# lilium_network register map
Vendor: Nordic Semiconductor; Series: nrfXX; File version: 1
CPU: CM33 r0p4, little endian, MPU, no FPU, 3 interrupt priority bits, 30 interrupts
Registers are 32-bit, read-write, reset 0x0 unless marked. A register's access mark holds for its fields unless they carry their own. Offsets are from the block's base; [hi:lo] are bit positions; lines under a group give offsets from that group; {n}, {i} and the like mark numbered series; 'fields as' and 'values as' point back to an identical list.

## RADIO (part 2 of 3) — 2.4 GHz radio
Base 0x41008000
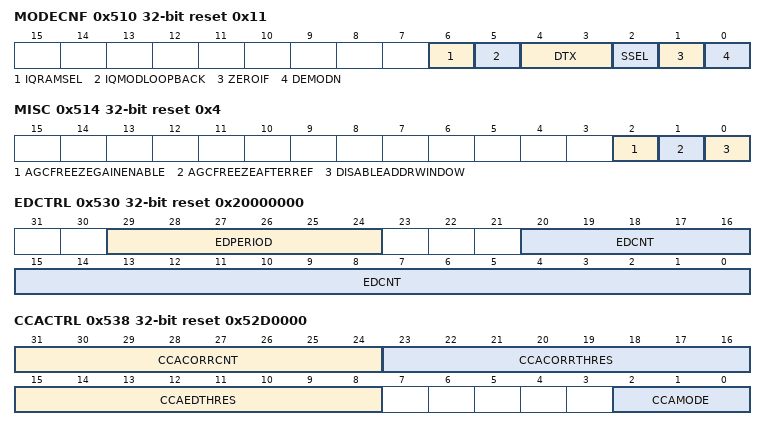
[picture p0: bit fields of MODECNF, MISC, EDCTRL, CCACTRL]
0x510 MODECNF reset 0x11 — Radio mode configuration register
  [6] IQRAMSEL — IQ RAM select
    0=off (IQ RAM select off); 1=on (IQ RAM select on)
  [5] IQMODLOOPBACK — Loopback from IQ modulator TODO: is it a good place?
    0=Off (Digital loopback off); 1=On (Digital loopback on)
  [4:3] DTX — Default TX value. Specifies what the RADIO will transmit when it is not started, i.e. between: RADIO.EVENTS_READY and RADIO.TASKS_START RADIO.EVENTS_END and RADIO.TASKS_START RADIO.EVENTS_END and RADIO.EVENTS_DISABLED)
    0=B1 (Transmit '1'); 1=B0 (Transmit '0'); 2=Center (Transmit center frequency When tuning the crystal for centre frequency, the RADIO must be set in DTX = Center mode to be able to achieve the expected accuracy. This is only a valid setting for Nrf_1Mbit, Nrf_2Mbit, Nrf_250kbit, Ble_1Mbit and Ble_2Mbit.)
  [2] SSEL — Sideband select
    0=Low (Low-side LO); 1=High-side LO
  [1] ZEROIF — Zero-IF mode
    0=Default mode (heterodyne); 1=Zero-IF mode
  [0] DEMODN — Demodulator mode override value
    0=Standard demodulator mode; 1=Hyper demodulator mode
0x514 MISC reset 0x4 — Misc configuration collection (to be renamed when more bits are defined)
  [2] AGCFREEZEGAINENABLE — Override AGC gain setting during CTE (from QOVERRIDE10)
    0=Adjust (AGC gain settings will keep adjusting during CTE); 1=Freeze (AGC gain settings will freeze (not keep adjusting) during CTE)
  [1] AGCFREEZEAFTERREF
    0=EntireCTE (Gain freeze will apply to whole CTE,); 1=AfterRefPeriod (Gain freeze will apply to only after reference period of CTE.)
  [0] DISABLEADDRWINDOW
    1=Disabled; 0=Enabled
0x520 STATE ro — Current radio state
  [3:0] STATE
    0=Disabled (RADIO is in the Disabled state); 1=RxRu (RADIO is in the RXRU state); 2=RxIdle (RADIO is in the RXIDLE state); 3=Rx (RADIO is in the RX state); 4=RxDisable (RADIO is in the RXDISABLED state); 9=TxRu (RADIO is in the TXRU state); 10=TxIdle (RADIO is in the TXIDLE state); 11=Tx (RADIO is in the TX state); 12=TxDisable (RADIO is in the TXDISABLED state)
0x530 EDCTRL reset 0x20000000 — IEEE 802.15.4 energy detect control TODO: review and maybe rename in IPS
  [29:24] EDPERIOD — IEEE 802.15.4 energy detect/cca period, 4us resolution
  [20:0] EDCNT — IEEE 802.15.4 energy detect loop count
0x534 EDSAMPLE ro — IEEE 802.15.4 energy detect level
  [7:0] EDLVL
0x538 CCACTRL reset 0x52D0000 — IEEE 802.15.4 clear channel assessment control
  [31:24] CCACORRCNT — Limit for occurances above CCACORRTHRES. When not equal to zero the corrolator based signal detect is enabled.
  [23:16] CCACORRTHRES — CCA correlator busy threshold. Only relevant to CarrierMode, CarrierAndEdMode, and CarrierOrEdMode.
  [15:8] CCAEDTHRES — CCA energy busy threshold. Used in all the CCA modes except CarrierMode.
  [2:0] CCAMODE — CCA mode of operation
    0=EdMode (Energy above threshold); 1=CarrierMode (Carrier seen); 2=CarrierAndEdMode (Energy above threshold AND carrier seen); 3=CarrierOrEdMode (Energy above threshold OR carrier seen); 4=EdModeTest1 (Energy above threshold test mode that will abort when first ED measurement over threshold is seen. No averaging.)
0x540 DATAWHITEIV reset 0x40 — Data whitening initial value TODO:move to FelisMAC
  [5:0] DATAWHITEIV
0x548 ACQINJ group — Unspecified
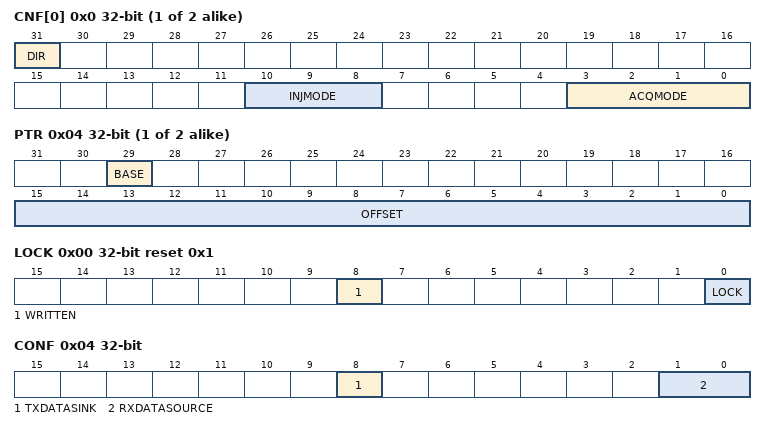
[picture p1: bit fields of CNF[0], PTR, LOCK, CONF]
  {0x0+4j} CNF[{j}] (j=0..1) — Description collection: Data acquisition capture mode
    [31] DIR — Data acquisition or injection
      0=Acq (Peripheral to memory); 1=Inj (Memory to peripheral)
    [10:8] INJMODE — Data hijack mode (Do not select the same SRC for one than more DMAs. otherwise higher index takes over control.)
      0=FeSrc (Pick up IQ samples from RAM as FrontEnd input (hijack ADC output)); 1=BbSrc (Pick up IQ samples from RAM as Radio BaseBand input); 2=TxSrc (Pick up Tx bits from RAM (skipping packet assembler as modulator input); 6=AdPllModSrc (Pick up arbitrary wave from RAM to ADPLL)
    [3:0] ACQMODE — Data acquisition capture mode
      0=AdcIQ (Logging ADCI and ADCQ); 2=AdcIQAndAgcGain (Logging ADCI, ADCQ and AGC gain settings); 3=AgcGainAndPkd (Logging AGC gain settings and peak detector outputs); 4=FeIQ (Logging FrontEnd sampleI and sampleQ); 5=BbIQ (Logging BaseBand I and Q); 6=BbStdOut (Logging BaseBand std demodulator outputs (original ones, not the delayed version)); 7=BbHypOut (Logging BaseBand hyp demodulator outputs); 8=BbStdHypMuxOut (Logging muxed demodulator outputs and flags); 12=AdPllTrace (ADPLL tracing)
{0x550+0x10*i} ACQINJDMA[{i}] (i=0..1) group — Unspecified
  0x00 ENABLE — Description cluster: Enable or disable data acquisition
    [0] ENABLE — Enable or disable data acquisition
      0=Disabled (Data acquisition is disabled); 1=Enabled (Data acquisition is enabled)
  0x04 PTR — Description cluster: ACQ DMA pointer
    [29] BASE, [15:0] OFFSET
  0x08 MAXCNT — Description cluster: Maximum number of 32-bit words to transfer
    [13:0] MAXCNT — Maximum number of 32-bit words to transfer
  0x0C AMOUNT ro — Description cluster: Number of 32-bit words transferred in the last transaction
    [13:0] AMOUNT — Number of 32-bit words transferred in the last transaction
0x570 TESTINTERFACE group — 2.4 GHz radio direct test interface
  0x00 TESTINTERFACE group — Unspecified
    0x00 LOCK ro reset 0x1 — Security LOCK for test interface
      [8] WRITTEN — Status bit indicating if write once register has been written to since last reset
        1=Written (Write once register has been written to and cannot be overwritten unless reset.); 0=Unwritten (Write once register has not been written to and can be overwritten.)
      [0] LOCK — Write once to permanently lock or unlock.
        1=Lock (Interface is locked and cannot be enabled.); 0=Unlock (Interface is unlocked and can be enabled.)
    0x04 CONF — CONFIG for PSEL test interface
      [8] TXDATASINK — Sink select for Tx Data input. TX clock source is always SphynxSupport
        0=FelisTx (TX data sink is FelisTx); 1=SphynxSupport (TX data sink is SphynxSupport)
      [1:0] RXDATASOURCE — Source select for Rx data GPIO output and Rx clock output. Can optionally output Tx data that is transmitted TX clock
        0=Standard (Data and clock source is from standard demodulator); 1=Hyper (Data and clock source is from hyper demodulator); 2=FelisTx (Data source is Tx data to SphynxSupport.); 3=MacTx (Data source is Tx data to FelisTx.)
  0x08 DEBUGPSEL group — Unspecified
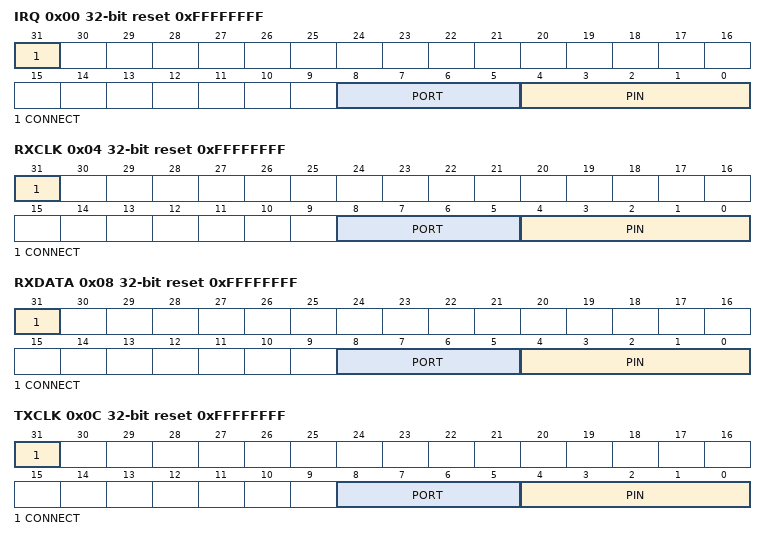
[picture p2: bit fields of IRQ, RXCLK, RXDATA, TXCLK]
    0x00 IRQ reset 0xFFFFFFFF — Pin select for RADIO irq
      [31] CONNECT — Connection
        1=Disconnected; 0=Connected
      [8:5] PORT — Port number
      [4:0] PIN — Pin number
    0x04 RXCLK reset 0xFFFFFFFF — Pin select for RXCLK
      fields as TESTINTERFACE.DEBUGPSEL.IRQ
    0x08 RXDATA reset 0xFFFFFFFF — Pin select for RXDATA
      fields as TESTINTERFACE.DEBUGPSEL.IRQ
    0x0C TXCLK reset 0xFFFFFFFF — Pin select for RADIO clock (direct mode, base band debug. txCk and ckDataIn signals)
      fields as TESTINTERFACE.DEBUGPSEL.IRQ
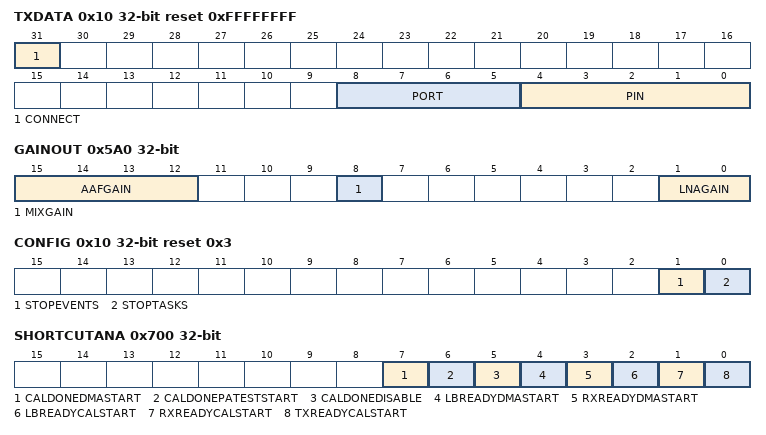
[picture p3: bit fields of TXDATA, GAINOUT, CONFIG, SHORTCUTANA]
    0x10 TXDATA reset 0xFFFFFFFF — Pin select for RADIO data (direct mode, base band debug. txRadioData and dataIn signals)
      fields as TESTINTERFACE.DEBUGPSEL.IRQ
0x5A0 GAINOUT ro — Gain readout (LNA_OUT_SPI for nrf52/53)
  [15:12] AAFGAIN, [8] MIXGAIN, [1:0] LNAGAIN
0x5B0 INTERCEPT group — Write 1 to a bit to arm the task/event at that index for a single intercept. Write 0 to a bit to disarm. After arming, the bit will be read out as 1 until the task/event has been intercepted or disarmed, after which it will be read out as 0. Both PPI-triggered and APB-triggered tasks will be intercepted. Only core-triggered events will be intercepted, not APB-triggered events.
  {0x0+4j} TASKS[{j}] (j=0..1) — Description collection:
    [31:0] ONEBITPERTASK
  {0x8+4j} EVENTS[{j}] (j=0..1) — Description collection:
    [31:0] ONEBITPEREVENT
  0x10 CONFIG reset 0x3 — Unspecified
    [1] STOPEVENTS, [0] STOPTASKS
0x700 SHORTCUTANA — Internal shortcuts for RADIO PHY
  [7] CALDONEDMASTART — Internal shortcut
  [6] CALDONEPATESTSTART — Internal shortcut
  [5] CALDONEDISABLE — Internal shortcut
  [4] LBREADYDMASTART — Internal shortcut
  [3] RXREADYDMASTART — Internal shortcut
  [2] LBREADYCALSTART — Internal shortcut
  [1] RXREADYCALSTART — Internal shortcut
  [0] TXREADYCALSTART — Internal shortcut
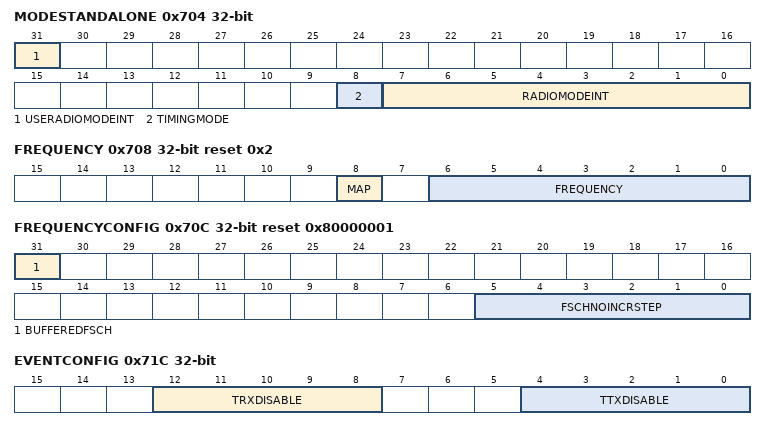
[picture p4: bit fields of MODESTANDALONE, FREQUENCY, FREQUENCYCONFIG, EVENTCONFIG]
0x704 MODESTANDALONE — Data rate and modulation when SPHYNX in standalone mode
  [31] USERADIOMODEINT — 0: use radioMode/radioModeUpdate from port (controlled from top), 1: use radioMode/radioModeUpdate from registers in this IP
  [8] TIMINGMODE — 0: Default ramp-up time, compatible with 180nm radio. 1: Fast ramp-up.
  [7:0] RADIOMODEINT — Internal radio mode consists of sSel, zeroIf, deModN and mode[3:0]
0x708 FREQUENCY reset 0x2
  [8] MAP — Channel map selection. 0: Channel map between 2400 MHZ to 2500 MHz, Frequency = 2400 + FREQUENCY (MHz). 1: Channel map between 2360 MHZ to 2460 MHz, Frequency = 2360 + FREQUENCY (MHz).
  [6:0] FREQUENCY — Radio channel frequency. Frequency = 2400 + FREQUENCY (MHz).
0x70C FREQUENCYCONFIG reset 0x80000001 — Configuration of frequency control
  [31] BUFFEREDFSCH — Set to high to buffer FREQUENCY register so that sub-modules in the MMI will only update next frequency config at TX_EN, RX_EN and LB_EN. Set to low if special test is needed for FS test.
  [5:0] FSCHNOINCRSTEP — Radio channel incremental step unit
0x710 TXPOWER — Output power
  [7:0] TXPOWER — RADIO output power
    {v}=Pos{v}dBm (+{v} dBm) (v=1..10); 0=0dBm; 255=Neg1dBm (-1 dBm); 254=Neg2dBm (-2 dBm); 252=Neg4dBm (-4 dBm); 248=Neg8dBm (-8 dBm); 244=Neg12dBm (-12 dBm); 240=Neg16dBm (-16 dBm); 236=Neg20dBm (-20 dBm); 226=Neg30dBm (-30 dBm); 216=Neg40dBm (-40 dBm); 186=Neg70dBm (-70 dBm)
0x714 TIFS — Interframe spacing in us
  [9:0] TIFS — Interframe spacing in us. Interframe space is the time interval between two consecutive packets. It is defined as the time, in microseconds, from the end of the last bit of the previous packet to the start of the first bit of the subsequent packet.
0x718 RSSISAMPLE ro reset 0x7F
  [6:0] RSSISAMPLE — RSSI sample result. The value of this register is read as a positive value while the actual received signal strength is a negative value. Actual received signal strength is therefore as follows: received signal strength = -A dBm.
0x71C EVENTCONFIG — Event configuration
  [12:8] TRXDISABLE — Transition time from RXDISABLE state to DISABLED state Configurable time, in us, between RADIO.EVENTS_END and RADIO.EVENTS_DISABLED when using the shortcut between RADIO.EVENTS_END and RADIO.TASKS_DISABLE. The minimum time between RADIO.TASKS_DISABLE and RADIO.EVENTS_DISABLED is described in electrical parameters. The minimum time will be used if the configured time is set shorter than the minimum time. Depending on configuration setting the DISABLED event may experience some jitter, see electrical parameters for more information. (unit: 1us)
  [4:0] TTXDISABLE — Transition time from TXDISABLE state to DISABLED state Configurable time, in us, between RADIO.EVENTS_END and RADIO.EVENTS_DISABLED when using the shortcut between RADIO.EVENTS_END and RADIO.TASKS_DISABLE. The minimum time between RADIO.TASKS_DISABLE and RADIO.EVENTS_DISABLED is described in the electrical parameters. The minimum time will be used if the configured time is set shorter than the minimum time. Depending on configuration setting the DISABLED event may experience some jitter, see electrical parameters for more information. Note: The RADIO shall be disabled as normal when DISABLE task is triggered, it is only the DISABLED event that can be delayed. Note: The TIFS mechanism shall not be affected by the value specified in this field. (unit: 1us)
0x720 CALIBRATION group — Unspecified
  0x00 TARGET — Select target for calibration
    [2:0] CALTARGET — Calibration target selection for calibration engine, 0: DC_CAL, 1: RC_CAL
  0x04 CONFIG — Configuration of manual calibration
    [31] CALMANUAL — 0: use hard-coded calibration timing, 1: use manual calibration timing above
    [29] CALINVERTCMP2 — 1: invert calCmp2 before it goes into calibration engine #2
    [28] CALINVERTCMP1 — 1: invert calCmp1 before it goes into calibration engine #1
    [26:24] CALBITS — Number of valid bits to be calibrated
    [23:16] CALTCOMPARE — Compare wait time
    [15:8] CALTSETTLE — Settle wait time
    [7:0] CALTSTART — Startup wait time
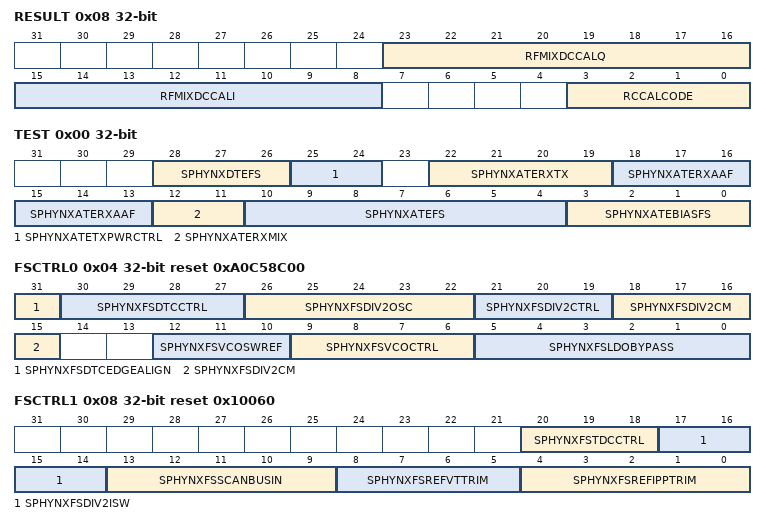
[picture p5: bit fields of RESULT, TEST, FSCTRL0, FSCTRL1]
  0x08 RESULT ro — Calibration result
    [23:16] RFMIXDCCALQ — Calibration result from DC offset calibration on channel Q
    [15:8] RFMIXDCCALI — Calibration result from DC offset calibration on channel I
    [3:0] RCCALCODE — Calibration result from RC calibration
0x730 SPHYNXANA group — Unspecified
  0x00 TEST — Control of analog and digital test bus output from Sphynx
    [28:26] SPHYNXDTEFS — Digital test enable for digital logic in analog macro
    [25:24] SPHYNXATETXPWRCTRL — Analog test enable for TX PWRCTRL
    [22:19] SPHYNXATERXTX — Analog test enable for RX TX
    [18:13] SPHYNXATERXAAF — Analog test enable for RX AAF
    [12:11] SPHYNXATERXMIX — Analog test enable for RX MIX
    [10:4] SPHYNXATEFS — Analog test enable for FS
    [3:0] SPHYNXATEBIASFS — Analog test enable for BIAS_FS
  0x04 FSCTRL0 reset 0xA0C58C00 — Control to frequency synthesizer of Sphynx
    [31] SPHYNXFSDTCEDGEALIGN — Resync at flip flop inside DTC
    [30:27] SPHYNXFSDTCCTRL — 0: controls bleed current from supply, 1: bypasses DTC to send XO out directly
    [26:22] SPHYNXFSDIV2OSC — Change back bias of NMOS in ROSC inside DIV2
    [21:19] SPHYNXFSDIV2CTRL — Spare, not used
    [18:15] SPHYNXFSDIV2CM — Set common mode for DIV2
    [12:10] SPHYNXFSVCOSWREF — FS swing calibration
    [9:6] SPHYNXFSVCOCTRL — Spare, not used
    [5:0] SPHYNXFSLDOBYPASS — Bypass FS LDOs
  0x08 FSCTRL1 reset 0x10060 — Control to frequency synthesizer of Sphynx
    [20:18] SPHYNXFSTDCCTRL — Spare, not used
    [17:14] SPHYNXFSDIV2ISW — Adjust voltage for back bias of injection switch
    [13:9] SPHYNXFSSCANBUSIN — DFT control/scan-in to AdPll. [4]: arstScan, [3]: scanTest, [2]: scanCk, [1]: scanEn, [0]: scanIn.
    [8:5] SPHYNXFSREFVTTRIM — For voltage tuning of reference
    [4:0] SPHYNXFSREFIPPTRIM — For current calibration
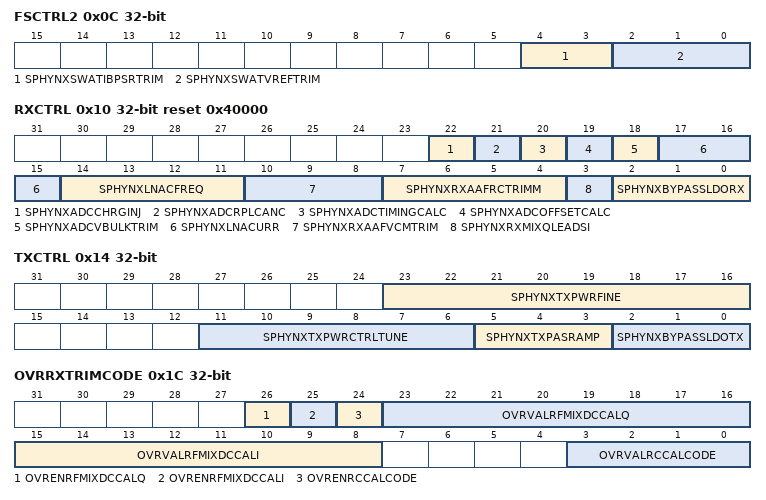
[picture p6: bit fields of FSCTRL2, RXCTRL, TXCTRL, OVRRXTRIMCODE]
  0x0C FSCTRL2 — Control to frequency synthesizer of Sphynx
    [4:3] SPHYNXSWATIBPSRTRIM — SWAT_TRIM_0V8[4:3] (default is 2b'00) for IBPSR trimming
    [2:0] SPHYNXSWATVREFTRIM — SWAT_TRIM_0V8[2:0] for SWAT_VREF trimming (default is 3b'000)
  0x10 RXCTRL reset 0x40000 — Control to receiver of Sphynx
    [22] SPHYNXADCCHRGINJ — Reference voltage charge injection mode
    [21] SPHYNXADCRPLCANC — Reference voltage ripple cancellation mode
    [20] SPHYNXADCTIMINGCALC — Calculation of ADC timing margin
    [19] SPHYNXADCOFFSETCALC — Enabling of offset calculation
    [18] SPHYNXADCVBULKTRIM — Trim bulks of LVT NFETs
    [17:15] SPHYNXLNACURR — LNA current setting
    [14:11] SPHYNXLNACFREQ — LNA center frequency settings
    [10:8] SPHYNXRXAAFVCMTRIM — VCM trim values for RX_AAF
    [7:4] SPHYNXRXAAFRCTRIMM — RC trim values for RX_AAF generated by RC_CAL
    [3] SPHYNXRXMIXQLEADSI — 1: output from MIX_AMP is Q leading I, 0 output from MIX_AMP is I leading Q
    [2:0] SPHYNXBYPASSLDORX — Bypass Rx LDOs
  0x14 TXCTRL — Control to transmitter of Sphynx
    [23:16] SPHYNXTXPWRFINE — Radio Tx output power fine tune
    [11:6] SPHYNXTXPWRCTRLTUNE — Digital input signal for tapping the resistor-ladder to create reference voltage in accordance with the desired peak
    [5:3] SPHYNXTXPASRAMP — TX PA ramp up/down control
    [2:0] SPHYNXBYPASSLDOTX — Bypass Tx LDOs
  0x18 MODEDEPENDENT — Mode dependent register of Sphynx
    [0] SPHYNXRXAAFFREQ — Select Rx IF frequency. 0=1MHz (for 1Mbps), 1=2MHz (for 2Mbps, 4Mbps)
  0x1C OVRRXTRIMCODE — Override trim codes to the receiver of Sphynx
    [26] OVRENRFMIXDCCALQ — For RXMIX_DCCAL_Q_0V8, 0: controlled by CalibrationEngine, 1: overridden by register
    [25] OVRENRFMIXDCCALI — For RXMIX_DCCAL_I_0V8, 0: controlled by CalibrationEngine, 1: overridden by register
    [24] OVRENRCCALCODE — For RCCAL_CODE_0V8, 0: controlled by CalibrationEngine, 1: overridden by register
    [23:16] OVRVALRFMIXDCCALQ — Override values on RXMIX_DCCAL_Q_0V8
    [15:8] OVRVALRFMIXDCCALI — Override values on RXMIX_DCCAL_I_0V8
    [3:0] OVRVALRCCALCODE — Override values on RCCAL_CODE_0V8
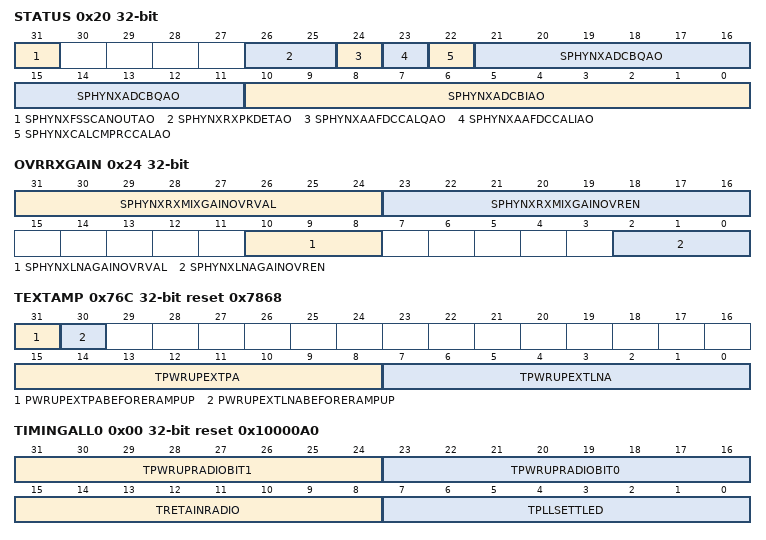
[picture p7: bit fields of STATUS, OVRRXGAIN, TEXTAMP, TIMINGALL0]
  0x20 STATUS ro — Readout raw status of signals output from Sphynx
    [31] SPHYNXFSSCANOUTAO — DFT Scan-out from AdPll
    [26:25] SPHYNXRXPKDETAO — Raw peak detector output from RX_PKDET
    [24] SPHYNXAAFDCCALQAO — Raw comparator output of DC calibration from RX_AAF Q channel
    [23] SPHYNXAAFDCCALIAO — Raw comparator output of DC calibration from RX_AAF I channel
    [22] SPHYNXCALCMPRCCALAO — Raw comparator output of RC calibration from RC_CAL
    [21:11] SPHYNXADCBQAO — Raw ADC Q channel output from RX_SAR2
    [10:0] SPHYNXADCBIAO — Raw ADC I channel output from RX_SAR2
  0x24 OVRRXGAIN — Analog rx gain override
    [31:24] SPHYNXRXMIXGAINOVRVAL — Override value for RXMIX_GAIN_0V8, each bit can be overriden individually
    [23:16] SPHYNXRXMIXGAINOVREN — Override enable for RXMIX_GAIN_0V8, each bit can be overriden individually
    [10:8] SPHYNXLNAGAINOVRVAL — Override value for LNA_GAIN_0V8, each bit can be overriden individually
    [2:0] SPHYNXLNAGAINOVREN — Override enable for LNA_GAIN_0V8, each bit can be overriden individually
0x76C TEXTAMP reset 0x7868 — Timing control of external RADIO amplifier (LNA/PA)
  [31] PWRUPEXTPABEFORERAMPUP — In legacy timing mode, pwrupExtPa can be powered on before starting to ramp up by setting this registers to 1
    0=AfterRampup (Power up external PA at (RADIO_rampup_start_time + TPWRUPEXTPA)); 1=BeforeRampup (Power up external PA at (RADIO_rampup_start_time - TPWRUPEXTPA))
  [30] PWRUPEXTLNABEFORERAMPUP — In legacy timing mode, pwrupExtLna can be powered on before starting to ramp up by setting this registers to 1
    0=AfterRampup (Power up external LNA at (RADIO_rampup_start_time + TPWRUPEXTLNA)); 1=BeforeRampup (Power up external LNA at (RADIO_rampup_start_time - TPWRUPEXTLNA))
  [15:8] TPWRUPEXTPA — Timing control of PwrupExtPa (unit: 0.25us)
  [7:0] TPWRUPEXTLNA — Timing control of PwrupExtLna (unit: 0.25us)
0x770 TIMINGENGINE group — Unspecified
  0x00 TIMINGALL0 reset 0x10000A0 — Timing parameters for signals activated in both Rx and Tx mode
    [31:24] TPWRUPRADIOBIT1 — Timing control of pwrupRadio[1] (unit: 0.25us)
    [23:16] TPWRUPRADIOBIT0 — Timing control of pwrupRadio[0] (unit: 0.25us)
    [15:8] TRETAINRADIO — Timing control of retainRadio (unit: 0.25us)
    [7:0] TPLLSETTLED — Timing control of pllSettled (unit: 0.25us)
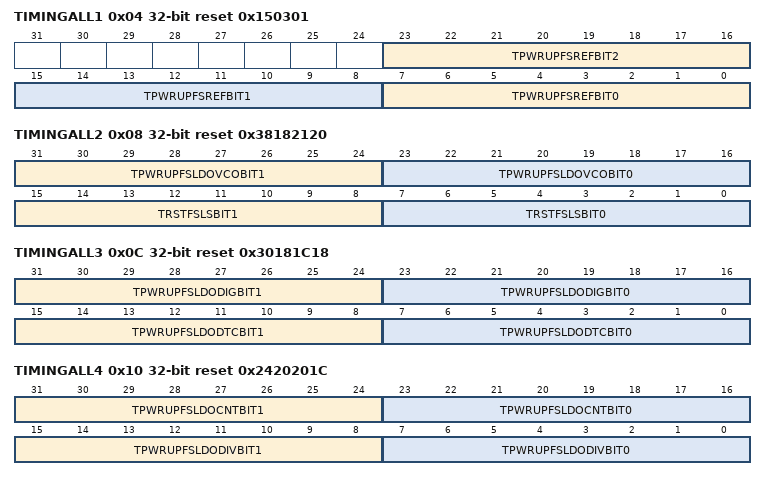
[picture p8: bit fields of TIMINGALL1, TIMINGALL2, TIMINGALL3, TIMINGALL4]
  0x04 TIMINGALL1 reset 0x150301 — Timing parameters for signals activated in both Rx and Tx mode
    [23:16] TPWRUPFSREFBIT2 — Timing control of PwrupFsRef[2] (unit: 0.25us)
    [15:8] TPWRUPFSREFBIT1 — Timing control of PwrupFsRef[1] (unit: 0.25us)
    [7:0] TPWRUPFSREFBIT0 — Timing control of PwrupFsRef[0] (unit: 0.25us)
  0x08 TIMINGALL2 reset 0x38182120 — Timing parameters for signals activated in both Rx and Tx mode
    [31:24] TPWRUPFSLDOVCOBIT1 — Timing control of PwrupFsLdoVco[1] (unit: 0.25us)
    [23:16] TPWRUPFSLDOVCOBIT0 — Timing control of PwrupFsLdoVco[0] (unit: 0.25us)
    [15:8] TRSTFSLSBIT1 — Timing control of RstFsLs[1] (unit: 0.25us)
    [7:0] TRSTFSLSBIT0 — Timing control of RstFsLs[0] (unit: 0.25us)
  0x0C TIMINGALL3 reset 0x30181C18 — Timing parameters for signals activated in both Rx and Tx mode
    [31:24] TPWRUPFSLDODIGBIT1 — Timing control of PwrupFsLdoDig[1] (unit: 0.25us)
    [23:16] TPWRUPFSLDODIGBIT0 — Timing control of PwrupFsLdoDig[0] (unit: 0.25us)
    [15:8] TPWRUPFSLDODTCBIT1 — Timing control of PwrupFsLdoDtc[1] (unit: 0.25us)
    [7:0] TPWRUPFSLDODTCBIT0 — Timing control of PwrupFsLdoDtc[0] (unit: 0.25us)
  0x10 TIMINGALL4 reset 0x2420201C — Timing parameters for signals activated in both Rx and Tx mode
    [31:24] TPWRUPFSLDOCNTBIT1 — Timing control of PwrupFsLdoCnt[1] (unit: 0.25us)
    [23:16] TPWRUPFSLDOCNTBIT0 — Timing control of PwrupFsLdoCnt[0] (unit: 0.25us)
    [15:8] TPWRUPFSLDODIVBIT1 — Timing control of PwrupFsLdoDiv[1] (unit: 0.25us)
    [7:0] TPWRUPFSLDODIVBIT0 — Timing control of PwrupFsLdoDiv[0] (unit: 0.25us)
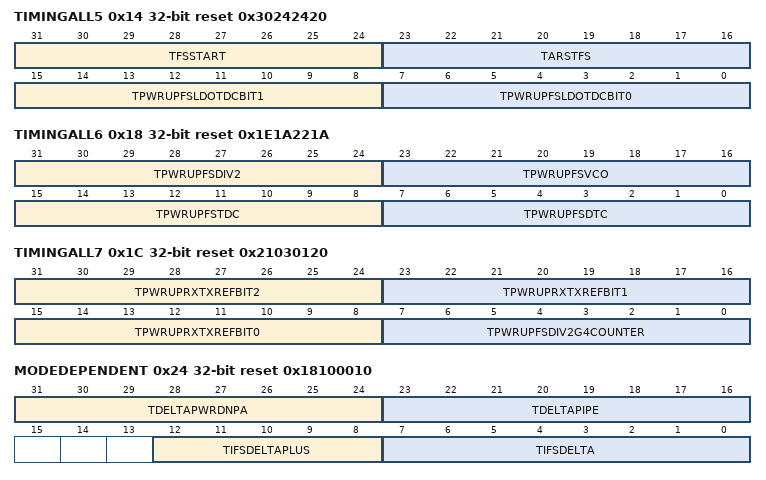
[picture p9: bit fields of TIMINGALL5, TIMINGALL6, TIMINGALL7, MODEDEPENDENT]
  0x14 TIMINGALL5 reset 0x30242420 — Timing parameters for signals activated in both Rx and Tx mode
    [31:24] TFSSTART — Timing control of FsStart (unit: 0.25us)
    [23:16] TARSTFS — Timing control of ArstFs (unit: 0.25us)
    [15:8] TPWRUPFSLDOTDCBIT1 — Timing control of PwrupFsLdoTdc[1] (unit: 0.25us)
    [7:0] TPWRUPFSLDOTDCBIT0 — Timing control of PwrupFsLdoTdc[0] (unit: 0.25us)
  0x18 TIMINGALL6 reset 0x1E1A221A — Timing parameters for signals activated in both Rx and Tx mode
    [31:24] TPWRUPFSDIV2 — Timing control of PwrupFsDiv2 (unit: 0.25us)
    [23:16] TPWRUPFSVCO — Timing control of PwrupFsVco (unit: 0.25us)
    [15:8] TPWRUPFSTDC — Timing control of PwrupFsTdc (unit: 0.25us)
    [7:0] TPWRUPFSDTC — Timing control of PwrupFsDtc (unit: 0.25us)
  0x1C TIMINGALL7 reset 0x21030120 — Timing parameters for signals activated in both Rx and Tx mode
    [31:24] TPWRUPRXTXREFBIT2 — Timing control of PwrupRxTxRef[2] (unit: 0.25us)
    [23:16] TPWRUPRXTXREFBIT1 — Timing control of PwrupRxTxRef[1] (unit: 0.25us)
    [15:8] TPWRUPRXTXREFBIT0 — Timing control of PwrupRxTxRef[0] (unit: 0.25us)
    [7:0] TPWRUPFSDIV2G4COUNTER — Timing control of PwrupFsDiv2g4Counter (unit: 0.25us)
  0x20 TIMINGALL8 reset 0x28 — Timing parameters for signals activated in both Rx and Tx mode
    [7:0] TRSTFSLSBIT2 — Timing control of RstFsLs[2] (unit: 0.25us)
  0x24 MODEDEPENDENT reset 0x18100010 — Mode dependent timing parameters
    [31:24] TDELTAPWRDNPA — Timing control of DeltaPwrdnPa (unit: 0.25us)
    [23:16] TDELTAPIPE — Timing control of DeltaPipe (unit: 0.25us)
    [12:8] TIFSDELTAPLUS — Timing control of IfsDeltaPlus (unit: 0.25us)
    [7:0] TIFSDELTA — Timing control of IfsDelta (unit: 0.25us)
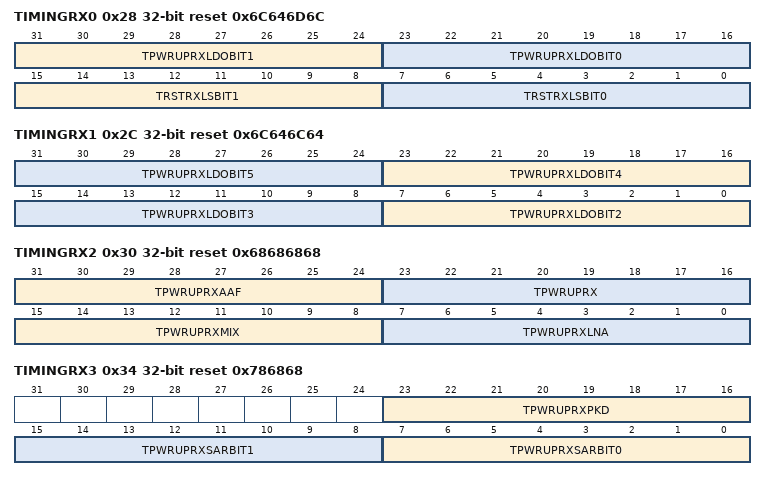
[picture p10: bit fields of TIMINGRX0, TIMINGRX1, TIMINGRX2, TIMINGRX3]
  0x28 TIMINGRX0 reset 0x6C646D6C — Timing parameters for signals activated in Rx mode
    [31:24] TPWRUPRXLDOBIT1 — Timing control of PwrupRxLdo[1] (unit: 0.25us)
    [23:16] TPWRUPRXLDOBIT0 — Timing control of PwrupRxLdo[0] (unit: 0.25us)
    [15:8] TRSTRXLSBIT1 — Timing control of RstRxLs[1] (unit: 0.25us)
    [7:0] TRSTRXLSBIT0 — Timing control of RstRxLs[0] (unit: 0.25us)
  0x2C TIMINGRX1 reset 0x6C646C64 — Timing parameters for signals activated in Rx mode
    [8n-9:8n-16] TPWRUPRXLDOBIT{n} (n=2..5) — Timing control of PwrupRxLdo[{n}] (unit: 0.25us)
  0x30 TIMINGRX2 reset 0x68686868 — Timing parameters for signals activated in Rx mode
    [31:24] TPWRUPRXAAF — Timing control of PwrupRxAaf (unit: 0.25us)
    [23:16] TPWRUPRX — Timing control of PwrupRx (unit: 0.25us)
    [15:8] TPWRUPRXMIX — Timing control of PwrupRxMix (unit: 0.25us)
    [7:0] TPWRUPRXLNA — Timing control of PwrupRxLna (unit: 0.25us)
  0x34 TIMINGRX3 reset 0x786868 — Timing parameters for signals activated in Rx mode
    [23:16] TPWRUPRXPKD — Spare register. Power up peak detector is now tied with power up mixer.
    [15:8] TPWRUPRXSARBIT1 — Timing control of PwrupRxSar[1] (unit: 0.25us)
    [7:0] TPWRUPRXSARBIT0 — Timing control of PwrupRxSar[0] (unit: 0.25us)
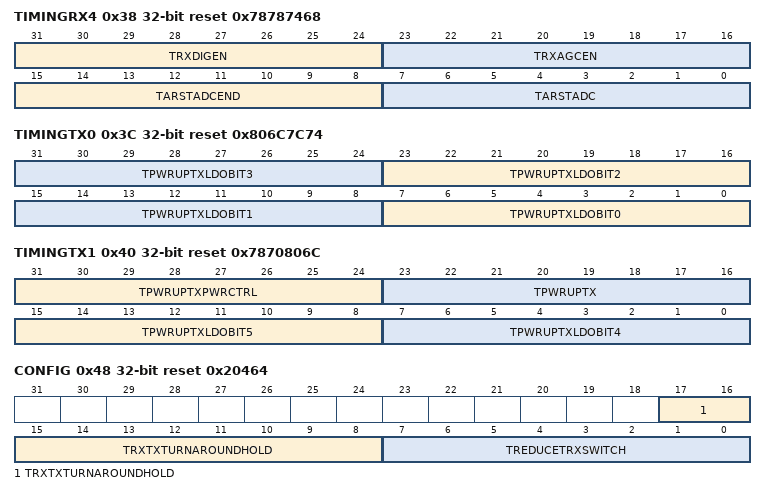
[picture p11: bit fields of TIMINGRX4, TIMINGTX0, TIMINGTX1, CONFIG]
  0x38 TIMINGRX4 reset 0x78787468 — Timing parameters for signals activated in Rx mode
    [31:24] TRXDIGEN — Timing control of RxDigEn (unit: 0.25us)
    [23:16] TRXAGCEN — Timing control of RxAgcEn (unit: 0.25us)
    [15:8] TARSTADCEND — Timing control of ArstAdcEnd (unit: 0.25us)
    [7:0] TARSTADC — Timing control of ArstAdc (unit: 0.25us)
  0x3C TIMINGTX0 reset 0x806C7C74 — Timing parameters for signals activated in Tx mode
    [8n+7:8n] TPWRUPTXLDOBIT{n} (n=0..3) — Timing control of PwrupTxLdo[{n}] (unit: 0.25us)
  0x40 TIMINGTX1 reset 0x7870806C — Timing parameters for signals activated in Tx mode
    [31:24] TPWRUPTXPWRCTRL — Timing control of PwrupTxPwrCtrl (unit: 0.25us)
    [23:16] TPWRUPTX — Timing control of PwrupTx (unit: 0.25us)
    [15:8] TPWRUPTXLDOBIT5 — Timing control of PwrupTxLdo[5] (unit: 0.25us)
    [7:0] TPWRUPTXLDOBIT4 — Timing control of PwrupTxLdo[4] (unit: 0.25us)
  0x44 TIMINGTX2 reset 0x78 — Timing parameters for signals activated in Tx mode
    [7:0] TPWRUPTXPA — Timing control of PwrupTxPa (unit: 0.25us)
  0x48 CONFIG reset 0x20464 — Configuration of timing control
    [17:8] TRXTXTURNAROUNDHOLD — Additional delay to hold Tx/Rx turnaround (unit: 0.25us)
    [7:0] TREDUCETRXSWITCH — Reduced timing for on-the-fly switch on both Rx->Tx and Tx->Rx (unit: 0.25us)
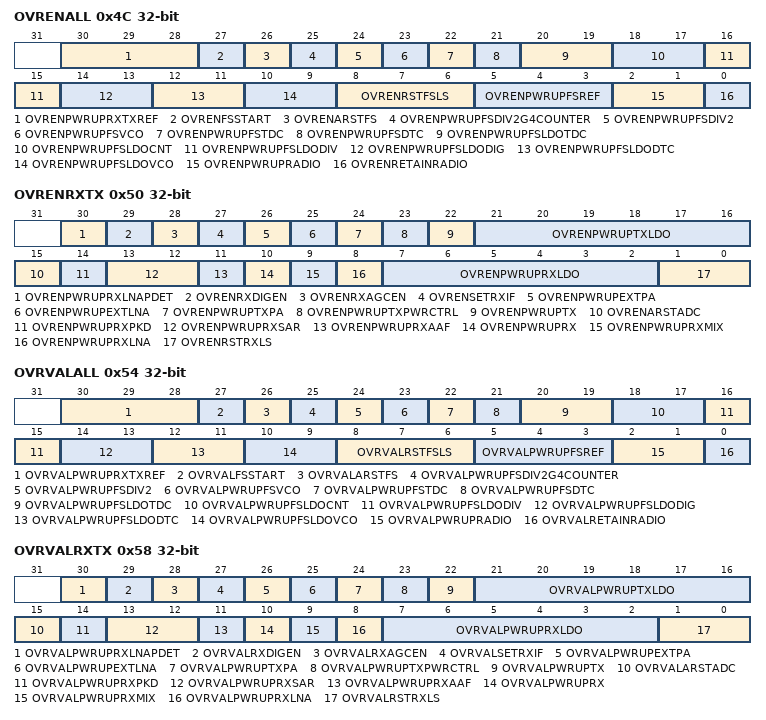
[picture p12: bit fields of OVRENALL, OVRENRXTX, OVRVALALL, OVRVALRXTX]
  0x4C OVRENALL — Enable or disable override of signals
    [30:28] OVRENPWRUPRXTXREF — Override enable of PwrupRxTxRef
    [27] OVRENFSSTART — Override enable of FsStart
    [26] OVRENARSTFS — Override enable of ArstFs
    [25] OVRENPWRUPFSDIV2G4COUNTER — Override enable of PwrupFsDiv2g4Counter
    [24] OVRENPWRUPFSDIV2 — Override enable of PwrupFsDiv2
    [23] OVRENPWRUPFSVCO — Override enable of PwrupFsVco
    [22] OVRENPWRUPFSTDC — Override enable of PwrupFsTdc
    [21] OVRENPWRUPFSDTC — Override enable of PwrupFsDtc
    [20:19] OVRENPWRUPFSLDOTDC — Override enable of PwrupFsLdoTdc
    [18:17] OVRENPWRUPFSLDOCNT — Override enable of PwrupFsLdoCnt
    [16:15] OVRENPWRUPFSLDODIV — Override enable of PwrupFsLdoDiv
    [14:13] OVRENPWRUPFSLDODIG — Override enable of PwrupFsLdoDig
    [12:11] OVRENPWRUPFSLDODTC — Override enable of PwrupFsLdoDtc
    [10:9] OVRENPWRUPFSLDOVCO — Override enable of PwrupFsLdoVco
    [8:6] OVRENRSTFSLS — Override enable of RstFsLs
    [5:3] OVRENPWRUPFSREF — Override enable of PwrupFsRef
    [2:1] OVRENPWRUPRADIO — Override enable of PwrupRadio
    [0] OVRENRETAINRADIO — Override enable of RetainRadio
  0x50 OVRENRXTX — Enable or disable override of signals
    [30] OVRENPWRUPRXLNAPDET — Override enable of PwrupRxLnaPdet
    [29] OVRENRXDIGEN — Override enable of rxDigEn
    [28] OVRENRXAGCEN — Override enable of rxAgcEn
    [27] OVRENSETRXIF — Override enable of setRxIf
    [26] OVRENPWRUPEXTPA — Override enable of PwrupExtPa
    [25] OVRENPWRUPEXTLNA — Override enable of PwrupExtLna
    [24] OVRENPWRUPTXPA — Override enable of PwrupTxPa
    [23] OVRENPWRUPTXPWRCTRL — Override enable of PwrupTxPwrCtrl
    [22] OVRENPWRUPTX — Override enable of PwrupTx
    [21:16] OVRENPWRUPTXLDO — Override enable of PwrupTxLdo
    [15] OVRENARSTADC — Override enable of ArstAdc
    [14] OVRENPWRUPRXPKD — Override enable of PwrupRxPkd
    [13:12] OVRENPWRUPRXSAR — Override enable of PwrupRxSar
    [11] OVRENPWRUPRXAAF — Override enable of PwrupRxAaf
    [10] OVRENPWRUPRX — Override enable of PwrupRx
    [9] OVRENPWRUPRXMIX — Override enable of PwrupRxMix
    [8] OVRENPWRUPRXLNA — Override enable of PwrupRxLna
    [7:2] OVRENPWRUPRXLDO — Override enable of PwrupRxLdo
    [1:0] OVRENRSTRXLS — Override enable of RstRxLs
  0x54 OVRVALALL — Set override values on signals
    [30:28] OVRVALPWRUPRXTXREF — Override value of PwrupRxTxRef
    [27] OVRVALFSSTART — Override value of FsStart
    [26] OVRVALARSTFS — Override value of ArstFs
    [25] OVRVALPWRUPFSDIV2G4COUNTER — Override value of PwrupFsDiv2g4Counter
    [24] OVRVALPWRUPFSDIV2 — Override value of PwrupFsDiv2
    [23] OVRVALPWRUPFSVCO — Override value of PwrupFsVco
    [22] OVRVALPWRUPFSTDC — Override value of PwrupFsTdc
    [21] OVRVALPWRUPFSDTC — Override value of PwrupFsDtc
    [20:19] OVRVALPWRUPFSLDOTDC — Override value of PwrupFsLdoTdc
    [18:17] OVRVALPWRUPFSLDOCNT — Override value of PwrupFsLdoCnt
    [16:15] OVRVALPWRUPFSLDODIV — Override value of PwrupFsLdoDiv
    [14:13] OVRVALPWRUPFSLDODIG — Override value of PwrupFsLdoDig
    [12:11] OVRVALPWRUPFSLDODTC — Override value of PwrupFsLdoDtc
    [10:9] OVRVALPWRUPFSLDOVCO — Override value of PwrupFsLdoVco
    [8:6] OVRVALRSTFSLS — Override value of RstFsLs
    [5:3] OVRVALPWRUPFSREF — Override value of PwrupFsRef
    [2:1] OVRVALPWRUPRADIO — Override value of PwrupRadio
    [0] OVRVALRETAINRADIO — Override value of RetainRadio
  0x58 OVRVALRXTX — Set override values on signals
    [30] OVRVALPWRUPRXLNAPDET — Override value of PwrupRxLnaPdet
    [29] OVRVALRXDIGEN — Override value of rxDigEn
    [28] OVRVALRXAGCEN — Override value of rxAgcEn
    [27] OVRVALSETRXIF — Override value of setRxIf
    [26] OVRVALPWRUPEXTPA — Override value of PwrupExtPa
    [25] OVRVALPWRUPEXTLNA — Override value of PwrupExtLna
    [24] OVRVALPWRUPTXPA — Override value of PwrupTxPa
    [23] OVRVALPWRUPTXPWRCTRL — Override value of PwrupTxPwrCtrl
    [22] OVRVALPWRUPTX — Override value of PwrupTx
    [21:16] OVRVALPWRUPTXLDO — Override value of PwrupTxLdo
    [15] OVRVALARSTADC — Override value of ArstAdc
    [14] OVRVALPWRUPRXPKD — Override value of PwrupRxPkd
    [13:12] OVRVALPWRUPRXSAR — Override value of PwrupRxSar
    [11] OVRVALPWRUPRXAAF — Override value of PwrupRxAaf
    [10] OVRVALPWRUPRX — Override value of PwrupRx
    [9] OVRVALPWRUPRXMIX — Override value of PwrupRxMix
    [8] OVRVALPWRUPRXLNA — Override value of PwrupRxLna
    [7:2] OVRVALPWRUPRXLDO — Override value of PwrupRxLdo
    [1:0] OVRVALRSTRXLS — Override value of RstRxLs
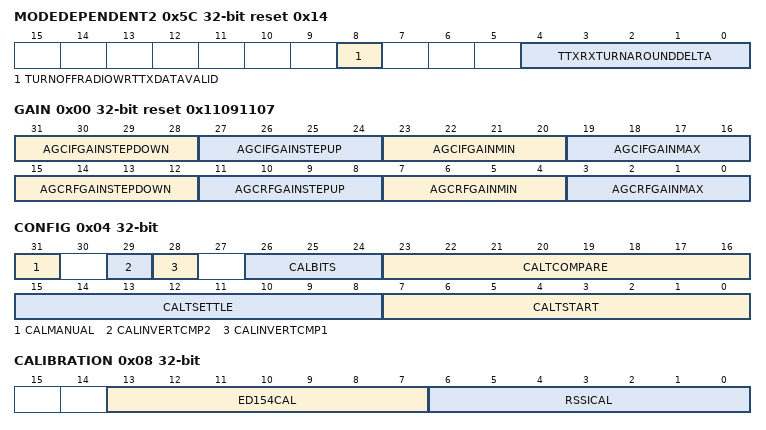
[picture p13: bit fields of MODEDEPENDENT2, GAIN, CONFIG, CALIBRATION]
  0x5C MODEDEPENDENT2 reset 0x14 — Mode dependent timing controls
    [8] TURNOFFRADIOWRTTXDATAVALID — Turn off radio with regards to txDataValid in addition to radioEn
    [4:0] TTXRXTURNAROUNDDELTA — Additional offset in Rx mode, for Rx to be able to be ready earlier, which is required for 2Mbps
0x7D0 RXAGC group — Unspecified
  0x00 GAIN reset 0x11091107 — Gain boundary settings and gain steps
    [31:28] AGCIFGAINSTEPDOWN — gain step for decreasing IF gain
    [27:24] AGCIFGAINSTEPUP — gain step for increasing IF gain
    [23:20] AGCIFGAINMIN — Minimum gain of IF gain
    [19:16] AGCIFGAINMAX — Maximum gain of IF gain
    [15:12] AGCRFGAINSTEPDOWN — gain step for decreasing RF gain
    [11:8] AGCRFGAINSTEPUP — gain step for increasing RF gain
    [7:4] AGCRFGAINMIN — Minimum gain of RF gain
    [3:0] AGCRFGAINMAX — Maximum gain of RF gain
  0x04 CONFIG reset 0x1230C3 — Configuration to adjust gain control loop
    [31] AGCENABLEGAINREVERT — Gain reversion. 0: reduce IF gain before RF gain, 1: reduce RF gain before IF gain.
    [30:29] AGCTOGGLE — Enable(1) or disable(0) functional testmode for AGC
    [28] AGCOVERRIDEGAIN — 0: AGC takes control of all gains, 1: Control all gains (aafGain, mixGain, lnaGain) from registers
    [23:22] AGCLNAOVERRIDE — Override value for lnaGain
    [21] AGCMIXOVERRIDE — Override value for mixGain
    [20:17] AGCAAFOVERRIDE — Override value for aafGain
    [16:11] AGCWAITPACKET — The number of clock cycles between each adjustment of the gain while addressMatch is high
    [10:5] AGCWAIT — The number of clock cycles between each adjustment of the gain while addressMatch is low
    [4:1] AGCRFPKDETRESETCOUNT — The number of clock cycles after the adjustment of gain that the reset signal to the RF peak detector is set high
    [0] AGCENABLEGAINSWITCH — Causes the RF gain to be decreased and the IF gain to be increased if the overall gain can be maintained
  0x08 CALIBRATION — Calibrate RSSI and Energy Detect values
    [13:7] ED154CAL — 802154 Energy Detect calibration value
    [6:0] RSSICAL — RSSI calibration value
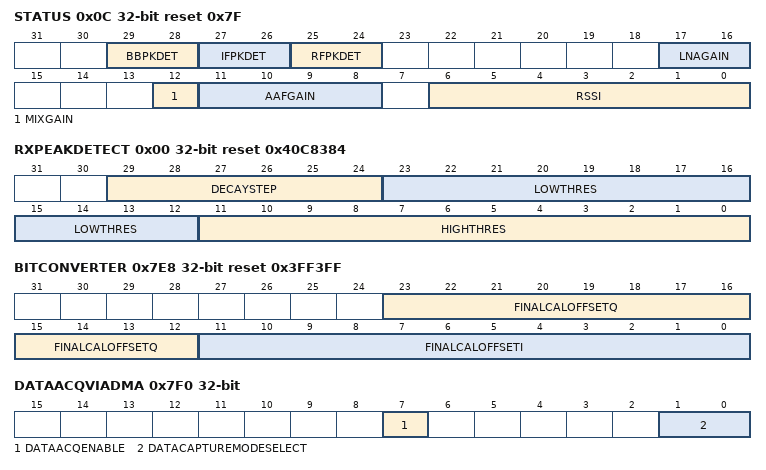
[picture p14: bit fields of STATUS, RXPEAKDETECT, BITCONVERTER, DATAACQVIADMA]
  0x0C STATUS ro reset 0x7F — Readout latest gain control status
    [29:28] BBPKDET — BB peak detector output. Represent state[1:0] in RxAgc.
    [27:26] IFPKDET — IF peak detector output. Represent state[3:2] in RxAgc.
    [25:24] RFPKDET — RF peak detector output after sync. Represent state[5:4] in RxAgc.
    [17:16] LNAGAIN — Raw LNA gain status
    [12] MIXGAIN — Raw mixer gain status
    [11:8] AAFGAIN — Raw AAF gain status
    [6:0] RSSI — Raw status of received signal strength indicator, directly from RxAgc without buffering
0x7E4 RXIF group — Unspecified
  0x00 RXPEAKDETECT reset 0x40C8384 — Configuration of IF Rx peak detector
    [29:24] DECAYSTEP — Constant output reduction step
    [23:12] LOWTHRES — Low threshold of IF peak detector. This valued is based on the 11-bits ADC of SPHYNX_ANA.
    [11:0] HIGHTHRES — High threshold of IF peak detector. This valued is based on the 11-bits ADC of SPHYNX_ANA.
0x7E8 BITCONVERTER reset 0x3FF3FF — Configuration of ADC output to digital front-end
  [23:12] FINALCALOFFSETQ — ADC offset compensation of channel Q (signed)
  [11:0] FINALCALOFFSETI — ADC offset compensation of channel I (signed)
0x7F0 DATAACQVIADMA — Data acquisition settings. Only available when INCLUDE_DMA is set to 1
  [7] DATAACQENABLE — Set high to enable data acquisition
  [1:0] DATACAPTUREMODESELECT — Which of 4 existing mode it is running (each mode correspond the a particular set of data to be logged)
0x7FC DEBUGRADIOPHY reset 0x100 — Debug for radio PHY
  [12] SHORTRCCALCODETOAAFRCTRIM — 1: short RCCAL_CODE[3:0] to RX_AAF_RCTRIMM[3:0]
  [11] RFMIXINVERTSIGNBIT — 1: Invert the sign bit of calibration code for DC offset calibration(invert DCCAL[4]). This inverts both channel I and Q.
  [10] TIEADCBQTOZERO — 0: output normal adcBinaryBQ, 1: tie adcBinaryBQ to zero
  [9] TIEADCBITOZERO — 0: output normal adcBinaryBI, 1: tie adcBinaryBI to zero
  [8] BUFFEREDTXPWR — Set to high to buffer TXPOWER so that sub-modules in the MMI will only update next tx power config at TX_EN, RX_EN and LB_EN. Set to low if special test is needed for Tx test.
  [7] OVRENTXPWR — Enable override of TX_PWR_0V8
  [4:0] OVRVALTXPWR — Override value of TX_PWR_0V8
0x800 ADPLLCOMMAND — Send or receive command directly to the AdPll digital island. Only write to this register when FSASYNCBUSBUSY returns 0
  [31] READ — When 1, a read transaction is initiated. When the event COMPLETETRANS is set, read back this register
  [27:0] ADPLLCOMMAND — Controls the asynch interface, bits[27:16] are address, bits [15:0] are command/data field
0x804 FSFREQFINETUNE — For finetuning the frequency
  [12:0] FSFREQFINETUNE — 2-complement number for fine-tuning the frequency in steps of 488.28 Hz
0x808 DEVIATION reset 0x55 — Frequency deviation for modulation
  [9:0] DEVIATION
0x80C MODRATE reset 0x2 — Select modulation rate
  [2:0] MODRATE
    0=250 kbps; 1=500 kbps; 2=1M (1 Mbps); 3=2M (2 Mbps); 4=4M (4 Mbps)
0x810 MODFILTERING reset 0x2 — Select gaussian filtering mode
  [2:0] MODFILTERING
    0=None (No filtering); 1=1bt00 (Gfsk Bt=1.00); 2=0bt60 (Gfsk Bt=0.60); 3=2bt00 (Gfsk Bt=2.00)
0x814 CUSTOMMODULATION — Enable reading from memory and passing data over to AdPll
  [0] ENABLE
0x818 FSCLOCKSELECT reset 0x1 — Set the clock source for the AdPll digital island
  [31] OVREN — Override enable for setting the clock switch. If 0, fsStart decides which clock to use. If 1, FSCLOCKSELECT.OVRVAL selects which clock to use
  [30] OVRVAL — Used instead of 'fsStart' if FSCLOCKSELECT.OVREN is set
  [8] STOP — Force-stopping the clock internally in the AdPll island
  [3:2] CORE — Set the clock source for the AdPll digital island when fsStart is low
  [1:0] INTERNAL — Set the clock source for the AdPll digital island when fsStart is high
0x81C FSUNITRIGCALVAL ro — Read the calibrated value for the universal trigger
  [4:0] FSUNITRIGCALVAL
0x820 FSUNITRIGMANUAL — Manual control of the uni trigger signals. Note that fsUniTriggerCalWord is controlled by writing to the separate register FSUNITRIGCALVAL
  [13:8] FSUNITRIGGERSRC — The fsUniTriggerCalSrc signal when using manual control
  [2] FSUNITRIGGERCALEN — The fsUniTriggerCalEn signal when using manual control
  [1] FSUNITRIGGER — The fsUniTrigger signal when using manual control
  [0] ENABLEMANUAL — Enable manual control
0x824 FSUNITRIGCALOUT ro — Read the signal directly from fsUniTriggerCalOut
  [1:0] FSUNITRIGCALOUT — Read the raw fsUniTriggerCalOut value
0x828 FSASYNCBUSCONF reset 0x4 — Some special settings for the asynchronous bus configuration
  [3] IGNORECLOCKSTARTED — The bus scheduler will not wait for AdPll to say clockStarted
  [2] CHECKSTATUSAUTO — When 1, check the first transaction during sending auto. If errorenous stop the state machine
  [1] DISABLEAUTOSETTING — Do not send settings at the beginning to AdPll
  [0] CHECKSTATUS — When 1, every write transaction uses 8 x 32 MHz clock cycles instead of 4 x 32 MHz clock cycles. Confirmation is received whether the transaction was actually received by AdPll.
0x82C FSASYNCBUSBUSY ro reset 0x1 — Status bit indicating whether the bus is currently busy or not
  [0] FSASYNCBUSBUSY — Whether the bus is currently busy or not
0x830 ADPLLCOMPANIONBACKDOORS reset 0x310 — This value is written to the AdPll when powering up the digital island
  [9:8] RELOADFREQWILLTRIGGER — 0: no relock, 1: first gear of TRK, 2: back to ACQ, 3: back to full lock
  [5:4] ONTHEFLYWILLTRIGGER — 0: no relock, 1: first gear of TRK, 2: back to ACQ, 3: back to full lock
  [3] OVRVALCK32MCORE — Whether ck32MCore is active or not when OVRENCK32MCORE is set. See also description of OVRENCK32MCORE
  [2] OVRENCK32MCORE — Make it possible to manually control whether ck32MCore is sent to the AdPll digital island. Needed to test complete clock silence in the AdPll island. It can also be used to enable the clock activity on the clock net even when the clock is not selected.
  [1] REQUESTCLOCKOVERRIDE — In normal operation we request clock when pwrupFsLdoDig0 is set. By setting this to 1, we will request clock even when pwrupFsLdoDig0. This may be useful for current measurements of FS_DIG
  [0] FLIPSSEL — If 0, we flip the interpretation of the sSel signal (to work around a bug if we have managed to flip it somewhere in the design process)
0x840 EXPECTEDPVTTOTRATIO reset 0x80000000 — This value is written to the AdPll when powering up the digital island
  [31] DONOTTRANSFER — When 1, we do not transfer this word to AdPll at power up
  [8:0] EXPECTEDPVTTOTRATIO — The ratio between PVT and the total cap ratio. Used for Estkmod, Estkdtc and TdcReadout
0x844 ESTKDTCVAL reset 0x80000000 — This value is written to the AdPll when powering up the digital island
  [31] DONOTTRANSFER — When 1, we do not transfer this word to AdPll at power up
  [11:0] ESTKDTVAL — The estimated kDTV value in typical
0x848 TXINTERFACEHFGAIN reset 0x80000000 — This value is written to the AdPll when powering up the digital island
  [31] DONOTTRANSFER — When 1, we do not transfer this word to AdPll at power up
  [9:0] TXINTERFACEHFGAIN — The gain for the HF path
0x84C TRACING — Enable tracing from AdPll
  [0] ENABLE
0x850 IFFREQ — Select between two different IF frequencies
  [0] HIGHIF
    0=1 MHz IF; 1=2 MHz IF
0x854 ADPLLCOMPANIONSTATE ro — State in the AdPllCompanion state machines
  [14:12] UNITRIGCALSTATE — The state of the universal trigger calibration routine
  [9:8] CLOCKSWITCHSTATE — The state of the clock switching state machine
  [5:4] BUSMASTERSTATE — The state of the async bus master
  [2:0] BUSSCHEDULERSTATE — The state of the state machine which sends commands automatically at startup
0x870 RELOADFREQINTERNAL — Non-official task: AdPll will reread the frequency input signal
  [0] TRIGGER
0x874 UNITRIGCALSTART — Non-official task: Start automatic universal trigger calibration
  [0] TRIGGER
0x878 FSSENDSETTINGS — Non-official task: Send the auto-settings to AdPll again. This also happens at every startup
  [0] TRIGGER
0x880 UNITRIGCALDONE — Non-official event: Start automatic universal trigger calibration
  [0] VAL
0x884 REJECTEDTRANS — Non-official event: The command written to AdPll was rejected because of an ongoing transaction
  [0] VAL
0x888 COMPLETETRANS — Non-official event: Completed a transaction to AdPll successfully (only when CHECKSTATUS is set)
  [0] VAL
0x88C FAILEDTRANS — Non-official event: Did not successfully complete a transaction to AdPll. (only when CHECKSTATUS is set)
  [0] VAL
{0x8A0+4i} ADPLLSTARTUPCOMMAND{i} reset 0x80000000 (i=0..7) — This value is written to the AdPll when powering up the digital island
  [31] DONOTTRANSFER — When 1, we do not transfer this word to AdPll at power up
  [27:16] ADDRESS — The address of the digital island to write to
  [15:0] VALUE — The value to be written the register in the digital island
0x8D0 ADPLLCOMPANIONINTEN — Unspecified
  [3:0] EVENTS — Interrupt enable register for events (unused since IRQ not connected)
0x8D4 ADPLLCOMPANIONINTENSET write-1-sets — Unspecified
  [3:0] EVENTS — Interrupt set register for events (unused since IRQ not connected)
0x8D8 ADPLLCOMPANIONINTENCLR write-1-clears — Unspecified
  [3:0] EVENTS — Interrupt clear register for events (unused since IRQ not connected)
0x8DC ADPLLCOMPANIONINTPEND ro — Unspecified
  [3:0] EVENTS
0x900 MODECONF reset 0x10006 — Mode specific configuration regiser
  [16] HIGHIFMODE — Selects mixing frequency. Setting this register to 0 halves the mixing frequency.
  [2:0] SATDLY — Mode dependent saturation delay for different modes
0x904 FESTATUS ro reset 0x1010 — Frontend readout register
  [27:16] MAGNITUDE — Magnitude output from BB peak detector
  [15] CALFIN — High when IQCal search finished
  [12:8] CALAMP — calAmp from IQCal
  [4:0] CALPHI — calPhi from IQCal
0x908 FECONFIG reset 0x10000005 — Config register
  [28] INVERTI — Invert I channel in case Q channel leads I
  [24] QDISABLE — Disable Q samples to save power
  [19:16] SCALECONST — A constant scaling that overrides dynamic scaling behaviour in the IQ Scaler. Value != 0 enables constant scaling.
  [13:8] SCALERDECAY — The number of clock cycles to wait before stepping down the internal memory for the scaling. The value 0 means that the decay feature is off.
  [7:0] ALPHA — Alpha for IIR filter used in logMag calculation
0x90C IQCALCONF reset 0x101028 — Gain and phase mismatch calibration control for I and Q
  [31] RUN — Run I and Q calibration procedure
    0=Stored (Using stored values for calPhi and calAmp); 1=Calib (Running calibration)
  [29:28] MODE — IQCal search mode
    0=Optimized search algorithm; 1=Exhaustive search; 2=Cancellation (Optimized search with cancellation.)
  [27] CALPHISIGN — Sign of calPhi value
  [20:16] CALPHI — Stored calPhi value
  [12:8] CALAMP — Stored calAmp value
  [7:0] IQCALWAIT — Settling time (in number of 16 MHz clock periods) for rssi input to stabilize
0x910 BBPKDETCONF reset 0x30140C8 — Configuration for baseband peak detector
  [29:24] DECAYSTEP — Constant output reduction step
  [23:12] LOWTHRESH — Low threshold for peak detector
  [11:0] HIGHTHRES — High threshold for peak detector
